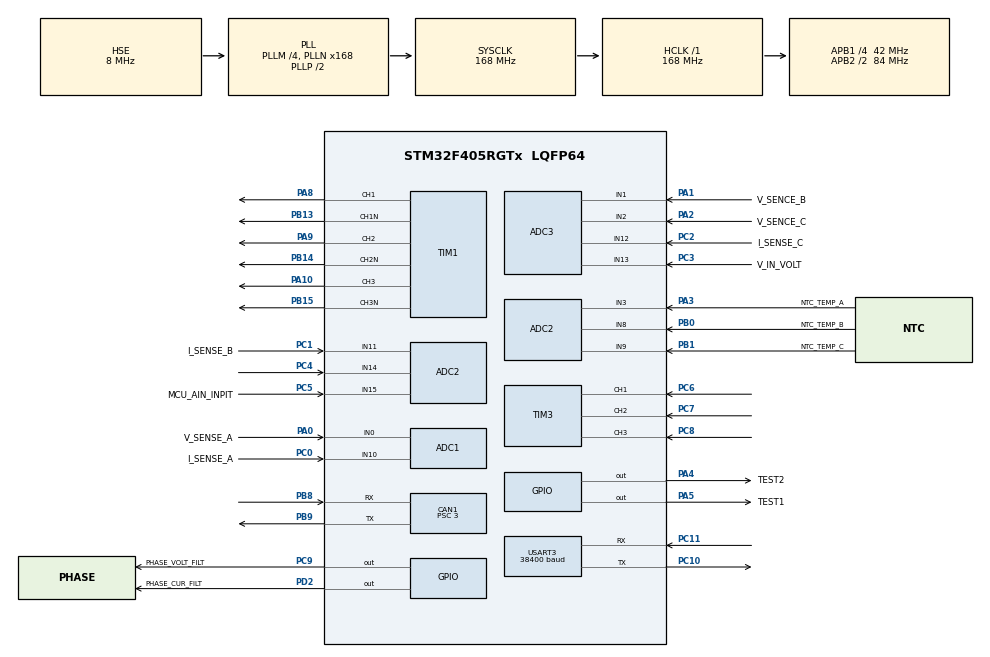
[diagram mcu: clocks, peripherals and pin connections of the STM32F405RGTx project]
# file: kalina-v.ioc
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ADC1.Channel-0\#ChannelRegularConversion=ADC_CHANNEL_TEMPSENSOR
ADC1.Channel-1\#ChannelInjectedConversion=ADC_CHANNEL_10
ADC1.Channel-2\#ChannelInjectedConversion=ADC_CHANNEL_0
ADC1.Channel-6\#ChannelInjectedConversion=ADC_CHANNEL_VREFINT
ADC1.Channel-7\#ChannelInjectedConversion=ADC_CHANNEL_TEMPSENSOR
ADC1.InjNumberOfConversion=4
ADC1.InjectedOffset-1\#ChannelInjectedConversion=0
ADC1.InjectedOffset-2\#ChannelInjectedConversion=0
ADC1.InjectedOffset-6\#ChannelInjectedConversion=0
ADC1.InjectedOffset-7\#ChannelInjectedConversion=0
ADC1.InjectedRank-1\#ChannelInjectedConversion=1
ADC1.InjectedRank-2\#ChannelInjectedConversion=2
ADC1.InjectedRank-6\#ChannelInjectedConversion=3
ADC1.InjectedRank-7\#ChannelInjectedConversion=4
ADC1.NbrOfConversion=1
ADC1.NbrOfConversionFlag=1
ADC1.Rank-0\#ChannelRegularConversion=1
ADC1.SamplingTime-0\#ChannelRegularConversion=ADC_SAMPLETIME_56CYCLES
ADC1.SamplingTime-1\#ChannelInjectedConversion=ADC_SAMPLETIME_56CYCLES
ADC1.SamplingTime-2\#ChannelInjectedConversion=ADC_SAMPLETIME_56CYCLES
ADC1.SamplingTime-6\#ChannelInjectedConversion=ADC_SAMPLETIME_56CYCLES
ADC1.SamplingTime-7\#ChannelInjectedConversion=ADC_SAMPLETIME_56CYCLES
ADC1.ScanConvMode=ENABLE
ADC1.master=1
ADC2.Channel-0\#ChannelRegularConversion=ADC_CHANNEL_15
ADC2.Channel-1\#ChannelInjectedConversion=ADC_CHANNEL_11
ADC2.Channel-11\#ChannelInjectedConversion=ADC_CHANNEL_8
ADC2.Channel-12\#ChannelInjectedConversion=ADC_CHANNEL_9
ADC2.Channel-2\#ChannelInjectedConversion=ADC_CHANNEL_3
ADC2.InjNumberOfConversion=4
ADC2.InjectedOffset-1\#ChannelInjectedConversion=0
ADC2.InjectedOffset-11\#ChannelInjectedConversion=0
ADC2.InjectedOffset-12\#ChannelInjectedConversion=0
ADC2.InjectedOffset-2\#ChannelInjectedConversion=0
ADC2.InjectedRank-1\#ChannelInjectedConversion=1
ADC2.InjectedRank-11\#ChannelInjectedConversion=3
ADC2.InjectedRank-12\#ChannelInjectedConversion=4
ADC2.InjectedRank-2\#ChannelInjectedConversion=2
ADC2.NbrOfConversion=1
ADC2.NbrOfConversionFlag=1
ADC2.Rank-0\#ChannelRegularConversion=1
ADC2.SamplingTime-0\#ChannelRegularConversion=ADC_SAMPLETIME_15CYCLES
ADC2.SamplingTime-1\#ChannelInjectedConversion=ADC_SAMPLETIME_56CYCLES
ADC2.SamplingTime-11\#ChannelInjectedConversion=ADC_SAMPLETIME_3CYCLES
ADC2.SamplingTime-12\#ChannelInjectedConversion=ADC_SAMPLETIME_3CYCLES
ADC2.SamplingTime-2\#ChannelInjectedConversion=ADC_SAMPLETIME_56CYCLES
ADC3.Channel-0\#ChannelRegularConversion=ADC_CHANNEL_12
ADC3.Channel-1\#ChannelInjectedConversion=ADC_CHANNEL_12
ADC3.Channel-2\#ChannelInjectedConversion=ADC_CHANNEL_1
ADC3.Channel-3\#ChannelInjectedConversion=ADC_CHANNEL_2
ADC3.Channel-4\#ChannelInjectedConversion=ADC_CHANNEL_13
ADC3.InjNumberOfConversion=4
ADC3.InjectedOffset-1\#ChannelInjectedConversion=0
ADC3.InjectedOffset-2\#ChannelInjectedConversion=0
ADC3.InjectedOffset-3\#ChannelInjectedConversion=0
ADC3.InjectedOffset-4\#ChannelInjectedConversion=0
ADC3.InjectedRank-1\#ChannelInjectedConversion=1
ADC3.InjectedRank-2\#ChannelInjectedConversion=2
ADC3.InjectedRank-3\#ChannelInjectedConversion=3
ADC3.InjectedRank-4\#ChannelInjectedConversion=4
ADC3.NbrOfConversion=1
ADC3.NbrOfConversionFlag=1
ADC3.Rank-0\#ChannelRegularConversion=1
ADC3.SamplingTime-0\#ChannelRegularConversion=ADC_SAMPLETIME_3CYCLES
ADC3.SamplingTime-1\#ChannelInjectedConversion=ADC_SAMPLETIME_3CYCLES
ADC3.SamplingTime-2\#ChannelInjectedConversion=ADC_SAMPLETIME_56CYCLES
ADC3.SamplingTime-3\#ChannelInjectedConversion=ADC_SAMPLETIME_3CYCLES
ADC3.SamplingTime-4\#ChannelInjectedConversion=ADC_SAMPLETIME_3CYCLES
CAN1.BS1=CAN_BS1_11TQ
CAN1.BS2=CAN_BS2_2TQ
CAN1.CalculateBaudRate=1000000
CAN1.CalculateTimeBit=1000
CAN1.CalculateTimeQuantum=71.42857142857143
CAN1.Prescaler=3
Dma.ADC2.0.Direction=DMA_PERIPH_TO_MEMORY
Dma.ADC2.0.FIFOMode=DMA_FIFOMODE_DISABLE
Dma.ADC2.0.Instance=DMA2_Stream2
Dma.ADC2.0.MemDataAlignment=DMA_MDATAALIGN_WORD
Dma.ADC2.0.MemInc=DMA_MINC_ENABLE
Dma.ADC2.0.Mode=DMA_NORMAL
Dma.ADC2.0.PeriphDataAlignment=DMA_PDATAALIGN_WORD
Dma.ADC2.0.PeriphInc=DMA_PINC_DISABLE
Dma.ADC2.0.Priority=DMA_PRIORITY_LOW
Dma.Request0=ADC2
Mcu.Family=STM32F4
Mcu.Name=STM32F405RGTx
Mcu.Package=LQFP64
NVIC.CAN1_RX0_IRQn=true\:6\:0\:true\:false\:true\:true\:true\:true
NVIC.CAN1_TX_IRQn=true\:6\:0\:true\:false\:true\:true\:true\:true
NVIC.DMA2_Stream2_IRQn=true\:0\:0\:false\:false\:true\:false\:true\:true
NVIC.PriorityGroup=NVIC_PRIORITYGROUP_4
PA0-WKUP.GPIO_Label=V_SENSE_A
PA0-WKUP.Signal=ADCx_IN0
PA1.GPIO_Label=V_SENCE_B
PA1.Signal=ADCx_IN1
PA10.Signal=S_TIM1_CH3
PA13.Mode=Serial_Wire
PA13.Signal=SYS_JTMS-SWDIO
PA14.Mode=Serial_Wire
PA14.Signal=SYS_JTCK-SWCLK
PA2.GPIO_Label=V_SENCE_C
PA2.Signal=ADCx_IN2
PA3.GPIO_Label=NTC_TEMP_A
PA3.Signal=ADCx_IN3
PA4.GPIO_Label=TEST2
PA4.GPIO_Speed=GPIO_SPEED_FREQ_HIGH
PA4.Signal=GPIO_Output
PA5.GPIO_Label=TEST1
PA5.Signal=GPIO_Output
PA8.Signal=S_TIM1_CH1
PA9.Signal=S_TIM1_CH2
PB0.GPIO_Label=NTC_TEMP_B
PB0.Signal=ADCx_IN8
PB1.GPIO_Label=NTC_TEMP_C
PB1.Signal=ADCx_IN9
PB13.Mode=PWM Generation1 CH1 CH1N
PB13.Signal=TIM1_CH1N
PB14.Mode=PWM Generation2 CH2 CH2N
PB14.Signal=TIM1_CH2N
PB15.Mode=PWM Generation3 CH3 CH3N
PB15.Signal=TIM1_CH3N
PB8.Mode=CAN_Activate
PB8.Signal=CAN1_RX
PB9.Mode=CAN_Activate
PB9.Signal=CAN1_TX
PC0.GPIO_Label=I_SENSE_A
PC0.Signal=ADCx_IN10
PC1.GPIO_Label=I_SENSE_B
PC1.Signal=ADCx_IN11
PC10.Mode=Asynchronous
PC10.Signal=USART3_TX
PC11.Mode=Asynchronous
PC11.Signal=USART3_RX
PC2.GPIO_Label=I_SENSE_C
PC2.Signal=ADCx_IN12
PC3.GPIO_Label=V_IN_VOLT
PC3.Signal=ADCx_IN13
PC4.Signal=ADCx_IN14
PC5.GPIO_Label=MCU_AIN_INPIT
PC5.Signal=ADCx_IN15
PC6.Signal=S_TIM3_CH1
PC7.Signal=S_TIM3_CH2
PC8.Signal=S_TIM3_CH3
PC9.GPIO_Label=PHASE_VOLT_FILT
PC9.Signal=GPIO_Output
PD2.GPIO_Label=PHASE_CUR_FILT
PD2.Signal=GPIO_Output
PH0-OSC_IN.Mode=HSE-External-Oscillator
PH0-OSC_IN.Signal=RCC_OSC_IN
PH1-OSC_OUT.Mode=HSE-External-Oscillator
PH1-OSC_OUT.Signal=RCC_OSC_OUT
ProjectManager.HeapSize=0x0
ProjectManager.StackSize=0x400
ProjectManager.TargetToolchain=MDK-ARM V5.32
RCC.48MHZClocksFreq_Value=84000000
RCC.AHBFreq_Value=168000000
RCC.APB1CLKDivider=RCC_HCLK_DIV4
RCC.APB1Freq_Value=42000000
RCC.APB1TimFreq_Value=84000000
RCC.APB2CLKDivider=RCC_HCLK_DIV2
RCC.APB2Freq_Value=84000000
RCC.APB2TimFreq_Value=168000000
RCC.CortexFreq_Value=168000000
RCC.HCLKFreq_Value=168000000
RCC.HSE_VALUE=8000000
RCC.HSI_VALUE=16000000
RCC.LSE_VALUE=32768
RCC.PLLM=4
RCC.PLLN=168
RCC.PLLSourceVirtual=RCC_PLLSOURCE_HSE
RCC.SYSCLKFreq_VALUE=168000000
RCC.SYSCLKSource=RCC_SYSCLKSOURCE_PLLCLK
RCC.VCOOutputFreq_Value=336000000
SH.ADCx_IN0.0=ADC1_IN0,IN0
SH.ADCx_IN1.0=ADC3_IN1,IN1
SH.ADCx_IN10.0=ADC1_IN10,IN10
SH.ADCx_IN11.0=ADC2_IN11,IN11
SH.ADCx_IN12.0=ADC3_IN12,IN12
SH.ADCx_IN13.0=ADC3_IN13,IN13
SH.ADCx_IN14.0=ADC2_IN14,IN14
SH.ADCx_IN15.0=ADC2_IN15,IN15
SH.ADCx_IN2.0=ADC3_IN2,IN2
SH.ADCx_IN3.0=ADC2_IN3,IN3
SH.ADCx_IN8.0=ADC2_IN8,IN8
SH.ADCx_IN9.0=ADC2_IN9,IN9
SH.S_TIM1_CH1.0=TIM1_CH1,PWM Generation1 CH1 CH1N
SH.S_TIM1_CH2.0=TIM1_CH2,PWM Generation2 CH2 CH2N
SH.S_TIM1_CH3.0=TIM1_CH3,PWM Generation3 CH3 CH3N
SH.S_TIM3_CH1.0=TIM3_CH1,Xored_Inputs_Hall_Sensor_Interface
SH.S_TIM3_CH2.0=TIM3_CH2,Xored_Inputs_Hall_Sensor_Interface
SH.S_TIM3_CH3.0=TIM3_CH3,Xored_Inputs_Hall_Sensor_Interface
TIM1.Channel-Output\ Compare4\ No\ Output=TIM_CHANNEL_4
TIM1.Channel-PWM\ Generation1\ CH1\ CH1N=TIM_CHANNEL_1
TIM1.Channel-PWM\ Generation2\ CH2\ CH2N=TIM_CHANNEL_2
TIM1.Channel-PWM\ Generation3\ CH3\ CH3N=TIM_CHANNEL_3
TIM1.CounterMode=TIM_COUNTERMODE_CENTERALIGNED2
TIM1.DeadTime=148
TIM3.IC1Filter=3
USART3.BaudRate=38400
USART3.VirtualMode=VM_ASYNC
VP_ADC1_TempSens_Input.Mode=IN-TempSens
VP_ADC1_Vref_Input.Mode=IN-Vrefint
VP_TIM1_VS_ClockSourceINT.Mode=Internal
VP_TIM1_VS_no_output4.Mode=Output Compare4 No Output
VP_TIM3_VS_ClockSourceINT.Mode=Internal
board=custom

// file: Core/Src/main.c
/* USER CODE BEGIN Header */
/**
  ******************************************************************************
  * @file           : main.c
  * @brief          : Main program body
  ******************************************************************************
  * @attention
  *
  * Copyright (c) 2024 STMicroelectronics.
  * All rights reserved.
  *
  * This software is licensed under terms that can be found in the LICENSE file
  * in the root directory of this software component.
  * If no LICENSE file comes with this software, it is provided AS-IS.
  *
  ******************************************************************************
  */
/* USER CODE END Header */
#include "main.h"
#include "adc.h"
#include "can.h"
#include "dma.h"
#include "tim.h"
#include "usart.h"
#include "gpio.h"

/* USER CODE BEGIN Includes */
#include "burst/burst.h"
/* USER CODE END Includes */

void SystemClock_Config(void);

int main(void)
{

  /* MCU Configuration--------------------------------------------------------*/

  /* Reset of all peripherals, Initializes the Flash interface and the Systick. */
  HAL_Init();

  /* Configure the system clock */
  SystemClock_Config();

  /* Initialize all configured peripherals */
  MX_GPIO_Init();
  MX_DMA_Init();
  MX_TIM1_Init();
  MX_ADC1_Init();
  MX_ADC2_Init();
  MX_ADC3_Init();
  MX_CAN1_Init();
  MX_TIM3_Init();
  MX_USART3_UART_Init();
  /* USER CODE BEGIN 2 */
	burst_begin();
	burst_start();
  /* USER CODE END 2 */

  /* Infinite loop */
  /* USER CODE BEGIN WHILE */
  while (1)
  {
		burst_frontend_loop();
    /* USER CODE END WHILE */

  }
}

void SystemClock_Config(void)
{
  RCC_OscInitTypeDef RCC_OscInitStruct = {0};
  RCC_ClkInitTypeDef RCC_ClkInitStruct = {0};

  /** Configure the main internal regulator output voltage
  */
  __HAL_RCC_PWR_CLK_ENABLE();
  __HAL_PWR_VOLTAGESCALING_CONFIG(PWR_REGULATOR_VOLTAGE_SCALE1);

  /** Initializes the RCC Oscillators according to the specified parameters
  * in the RCC_OscInitTypeDef structure.
  */
  RCC_OscInitStruct.OscillatorType = RCC_OSCILLATORTYPE_HSE;
  RCC_OscInitStruct.HSEState = RCC_HSE_ON;
  RCC_OscInitStruct.PLL.PLLState = RCC_PLL_ON;
  RCC_OscInitStruct.PLL.PLLSource = RCC_PLLSOURCE_HSE;
  RCC_OscInitStruct.PLL.PLLM = 4;
  RCC_OscInitStruct.PLL.PLLN = 168;
  RCC_OscInitStruct.PLL.PLLP = RCC_PLLP_DIV2;
  RCC_OscInitStruct.PLL.PLLQ = 4;
  if (HAL_RCC_OscConfig(&RCC_OscInitStruct) != HAL_OK)
  {
    Error_Handler();
  }

  /** Initializes the CPU, AHB and APB buses clocks
  */
  RCC_ClkInitStruct.ClockType = RCC_CLOCKTYPE_HCLK|RCC_CLOCKTYPE_SYSCLK
                              |RCC_CLOCKTYPE_PCLK1|RCC_CLOCKTYPE_PCLK2;
  RCC_ClkInitStruct.SYSCLKSource = RCC_SYSCLKSOURCE_PLLCLK;
  RCC_ClkInitStruct.AHBCLKDivider = RCC_SYSCLK_DIV1;
  RCC_ClkInitStruct.APB1CLKDivider = RCC_HCLK_DIV4;
  RCC_ClkInitStruct.APB2CLKDivider = RCC_HCLK_DIV2;

  if (HAL_RCC_ClockConfig(&RCC_ClkInitStruct, FLASH_LATENCY_5) != HAL_OK)
  {
    Error_Handler();
  }
}

void Error_Handler(void)
{
  /* USER CODE BEGIN Error_Handler_Debug */
  /* User can add his own implementation to report the HAL error return state */
	burst_crash();
  /* USER CODE END Error_Handler_Debug */
}
